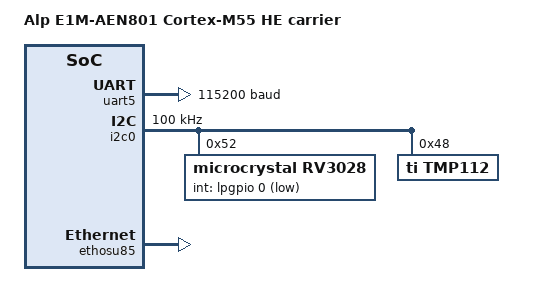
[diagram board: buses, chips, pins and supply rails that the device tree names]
/*
 * Copyright (c) 2026 Alp Lab AB
 * SPDX-License-Identifier: Apache-2.0
 * Auto-generated by `scripts/alp_project.py --emit zephyr-board` from
 * metadata/e1m_modules/E1M-AEN801.yaml + metadata/socs/alif/ensemble/e8.json + metadata/e1m_modules/aen/on-module-links.yaml.
 * DO NOT EDIT BY HAND -- regenerate.
 *
 * E1M-AEN801 (Alif Ensemble E8, AE822FA0E5597LS0) Cortex-M55-HE carrier,
 * for the Alp E1M-EVK.
 *
 * Reuses the upstream Alif E8 SoC + RTSS-HE cluster devicetree and:
 *   - retargets the console from the DevKit's UART2 to the E1M carrier console
 *     (Alif UART5, P3_4/P3_5 -- the E1M edge "UART0");
 *   - runs boot + storage from on-die MRAM only.  The SoM's OSPI0 NOR
 *     (MX25UM25645) + HyperRAM (W958D8NB) are BOM-optional and NOT populated
 *     on the current batch, so there is no external XIP / flash device;
 *   - lays down a production MCUboot partition map in MRAM.
 *
 * NOTE (AMP, #1069): HE's slot0 lives in its OWN disjoint MRAM window,
 * physically separate from HP's -- both cores' images can be
 * resident in MRAM at once (see the partition map below and
 * metadata/e1m_modules/E1M-AEN801.yaml `memory_map:`).  OTA is DEFERRED
 * (CONFIG_SINGLE_APPLICATION_SLOT=y, no secondary/scratch slot): the
 * per-core code slots (HE 2688 KiB + HP 2688 KiB) share the
 * 5632 KiB App MRAM with boot, storage and the NPU MRAM-model
 * budget -- see zephyr/sysbuild/aen/README.md for the sizing rationale.
 *
 * Inter-core IPC (the APSS<->RTSS-HE MHUv2 doorbell pair) + the remaining
 * on-module peripheral buses (GPIO / SPI / Ethernet) are added alongside the
 * alp-sdk Alif peripheral drivers; this base wires boot, console and the
 * on-module BRD_I2C housekeeping bus (RTC + temperature sensor, below).
 */

/dts-v1/;

#include <alif/ensemble/ae822fa0e5597ls0.dtsi>
#include <alif/ensemble/common/ensemble_rtss_he.dtsi>
#include <alif/ensemble_e8_peripherals.dtsi>
#include <zephyr/dt-bindings/gpio/gpio.h>
#include <zephyr/dt-bindings/i2c/i2c.h>
#include "alp_e1m_aen801_m55_he-pinctrl.dtsi"

/ {
	model = "Alp E1M-AEN801 Cortex-M55 HE carrier";
	compatible = "alp,e1m-aen801-m55-he";

	chosen {
		zephyr,flash = &mram_storage;
		/*
		 * MCUboot's flash_map_extended.c derives FLASH_DEVICE_BASE /
		 * FLASH_DEVICE_ID from zephyr,flash-controller (the controller
		 * node, NOT the soc-nv-flash child) -- mirrors the fork's
		 * e1.dtsi chosen.  Without it MCUboot's flash_map fails to link.
		 */
		zephyr,flash-controller = &mram;
		zephyr,sram = &dtcm;
		zephyr,console = &uart5;
		zephyr,shell-uart = &uart5;
		zephyr,code-partition = &slot0_partition;
	};
};

/*
 * ITCM/DTCM global_base -- central CPU-local -> system-bus address translation.
 *
 * hal_alif's soc_memory_map.h local_to_global() translates a CPU-local TCM
 * pointer into the address other bus masters (the Ethos-U NPU AXI master, the
 * SD/DMA controllers) must be programmed with, by reading
 * DT_PROP(DT_NODELABEL(itcm|dtcm), global_base).  Upstream Zephyr's
 * arm,itcm/arm,dtcm bindings (ensemble_rtss_he.dtsi, included above) declare no
 * such property, so re-`compatible` the nodes onto the alp-sdk
 * alif,itcm/alif,dtcm bindings (zephyr/dts/bindings/memory-controllers/), which
 * require global_base.  Done here in the per-core board (not a per-example
 * overlay) so every HE app on this board inherits the same translation.
 *
 * Values transcribed from the Apache-2.0 zephyr_alif fork
 * dts/arm/alif/ensemble/common/ensemble_rtss_he.dtsi:
 *   itcm global_base = 0x58000000  (also bench-known)
 *   dtcm global_base = 0x58800000
 * These are the RTSS-HE global TCM aliases; the RTSS-HP core uses a different
 * window (0x50000000 / 0x50800000), set in the _hp board dts.
 */
&itcm {
	/* fork ensemble_rtss_he.dtsi: itcm compatible = "alif,itcm" */
	compatible = "alif,itcm";
	/* fork ensemble_rtss_he.dtsi: itcm global_base = <0x58000000> */
	global_base = <0x58000000>;
};

&dtcm {
	/* fork ensemble_rtss_he.dtsi: dtcm compatible = "alif,dtcm" */
	compatible = "alif,dtcm";
	/* fork ensemble_rtss_he.dtsi: dtcm global_base = <0x58800000> */
	global_base = <0x58800000>;
};

/*
 * On-die MRAM as a real flash controller (ADR 0017 Tier-2).
 *
 * Upstream Zephyr's E8 SoC dtsi exposes the MRAM only as a memory region
 * (`mram: flash@80000000`, compatible "zephyr,memory-region","soc-nv-flash"):
 * XIP-readable but with NO flash driver, so FLASH_HAS_DRIVER_ENABLED stays
 * unset and MCUboot's flash_map has nothing to read/write slot0 with.
 *
 * We retarget the upstream `&mram` node into the fork's flash-controller
 * hierarchy WITHOUT editing upstream zephyr/: override `&mram`'s compatible to
 * the controller compatible "alif,mram-flash-controller" (which the in-tree
 * flash_mram_alif driver binds, setting FLASH_HAS_DRIVER_ENABLED), and add a
 * `mram_storage` soc-nv-flash child carrying the program/erase geometry the
 * driver reads (DT_NODELABEL(mram_storage): erase-block-size / write-block-size
 * / reg).  This mirrors the fork e1.dtsi node structure exactly (controller
 * `mram_flash@80000000` + `mram_storage@80000000` soc-nv-flash child); the only
 * difference is we reuse the upstream `mram` nodelabel as the controller rather
 * than declaring a fresh `mram_flash` node, since upstream owns the node.
 *
 * MRAM partition map (this HE core's 2944 KiB view of the
 * 5632 KiB App MRAM) for the sysbuild/aen MCUboot profile (MCUboot + a
 * signed application image, CONFIG_SINGLE_APPLICATION_SLOT=y -- no OTA/swap
 * slot, deferred per #1069).  Offsets are relative to the soc-nv-flash child
 * base (MRAM 0x80000000).  HP's disjoint slot0 window is NOT a
 * partition in this table (it's outside this core's own view); see
 * metadata/e1m_modules/E1M-AEN801.yaml `memory_map:` for the full physical map:
 *
 *   mcuboot  0x000000  64 KiB
 *   image-0  0x010000  2688 KiB   (primary slot, code-partition)
 *   reserved 0x550000  64 KiB   (ex-scratch; unused, OTA deferred)
 *   storage  0x560000  96 KiB    (settings / NVS)
 *   atoc     0x578000  32 KiB    (SE-owned: SETOOLS top-anchors the ATOC here -- do NOT write, #1289)
 *                      = 2944 KiB (of 5632 KiB App MRAM total)
 *
 * MRAM-only: the SoM OSPI NOR + HyperRAM are not populated on this batch, so
 * boot, this core's own slot0, reserved headroom, and storage all live in MRAM.
 */
&mram {
	compatible = "alif,mram-flash-controller";
	#address-cells = <1>;
	#size-cells = <1>;
	/*
	 * Drop the upstream memory-region properties: this node is no longer a
	 * "zephyr,memory-region" (it is a flash controller now), and the
	 * controller addresses its soc-nv-flash child by absolute `reg`, not via
	 * `ranges`.  flash-controller.yaml / base.yaml declare neither property,
	 * so they must be removed or DT binding-check fails.
	 */
	/delete-property/ zephyr,memory-region;
	/delete-property/ ranges;

	mram_storage: mram_storage@80000000 {
		compatible = "soc-nv-flash";
		reg = <0x80000000 DT_SIZE_K(5632)>;
		erase-block-size = <1024>;
		write-block-size = <16>;

		partitions {
			compatible = "fixed-partitions";
			#address-cells = <1>;
			#size-cells = <1>;

			boot_partition: partition@0 {
				label = "mcuboot";
				reg = <0x0 DT_SIZE_K(64)>;
			};

			slot0_partition: partition@10000 {
				label = "image-0";
				reg = <0x10000 DT_SIZE_K(2688)>;
			};

			reserved_partition: partition@550000 {
				label = "reserved";
				reg = <0x550000 DT_SIZE_K(64)>;
			};

			storage_partition: partition@560000 {
				label = "storage";
				reg = <0x560000 DT_SIZE_K(96)>;
			};

			atoc_partition: partition@578000 {
				label = "atoc";
				reg = <0x578000 DT_SIZE_K(32)>;
			};
		};
	};
};

/* Carrier console: Alif UART5 on P3_4 (RX) / P3_5 (TX), 115200 8N1. */
&uart5 {
	status = "okay";
	pinctrl-0 = <&pinctrl_uart5>;
	pinctrl-names = "default";
	current-speed = <115200>;
};

/*
 * BRD_I2C -- the on-module housekeeping bus: SoC I2C0 in its function-C
 * muxing (P7_0 SDA / P7_1 SCL), NOT the slave-only LPI2C0 it was
 * believed to be before #1848.  Driven by UPSTREAM
 * Zephyr i2c_dw ("snps,designware-i2c"), ADR 0017 Tier-1 -- no vendored code.
 *
 * ISOLATED: R93/R94 (the 0-ohm bridge to the I2C2/EEPROM segment) are DNP, so
 * the 24C128 manifest EEPROM is NOT on this bus -- it stays on i2c2.  The
 * OPTIGA Trust M (IC1, @0x30) is DNP=1 on this batch and so has NO node here;
 * its silence is a negative control, not a fault.
 *
 * Both device drivers are upstream and Kconfig `default y` on their own
 * DT_HAS_*_ENABLED, so an app needs only CONFIG_RTC / CONFIG_SENSOR in its
 * prj.conf -- the board layer deliberately forces neither.
 */
&i2c0 {
	status = "okay";
	pinctrl-0 = <&pinctrl_i2c0>;
	pinctrl-names = "default";
	clock-frequency = <I2C_BITRATE_STANDARD>;

	/*
	 * E1M-AEN-2626-R2 components CSV: U21 = RV-3028-C7, DNP=0 fitted. Bench
	 * 2026-09-05: ACKs at 0x52, ID register 0x28 reads 0x44, and the seconds
	 * register advanced 0x01 -> 0x02, so the oscillator is RUNNING. CAVEAT for
	 * docs and examples: with no VBACKUP cell the RTC does NOT retain time or a
	 * pending alarm across a power cycle on this batch.
	 */
	rv3028: rtc@52 {
		compatible = "microcrystal,rv3028";
		reg = <0x52>;
		backup-switch-mode = "disabled";
		int-gpios = <&lpgpio 0 GPIO_ACTIVE_LOW>;
	};

	/*
	 * E1M-AEN-2626-R2 components CSV: U20 = TMP112DIDPWR, DNP=0 fitted, ADD0 tied
	 * to 0V. The TMP112 strap table is ADD0->GND = 0x48, ->V+ = 0x49, ->SDA =
	 * 0x4A, ->SCL = 0x4B, so 0x48 is the DESIGN address. ANOMALY, do not "fix"
	 * this to match it: one bench unit (2026-09-05) answered at 0x40 -- not a
	 * legal TMP112 address at all -- while confirming a three-of-three TMP112
	 * register fingerprint there (CONFIG=0x60a0, T_LOW=0x4b00, T_HIGH=0x5000, the
	 * datasheet power-on defaults; read 28.062 degC). That points at ADD0 not
	 * actually sitting at GND on that module (suspected open joint on U20 pin 3):
	 * a defect on ONE unit, not the design. The shipped devicetree carries 0x48;
	 * examples tolerate and report the observed 0x40.
	 */
	tmp112: tmp112@48 {
		compatible = "ti,tmp112";
		reg = <0x48>;
	};
};

/*
 * lpgpio -- needed so the RV-3028 alarm on P15_0 (RTC_ALARM, bit 0 =>
 * IRQ 171) is usable as an interrupt source.  Active LOW,
 * open-drain, pulled up on-module by R98 (100k to +1V8, FITTED).  The pad
 * itself is muxed in the pinctrl dtsi's BRD_I2C group (that binding has no
 * pinctrl-0 of its own).
 *
 * The AE822 DFP warns for port 15: "Note that LPGPIO_CTRL_n register has a
 * different layout!". That is the most likely bench failure on this alarm path
 * and must NOT be mistaken for an RTC fault -- if the alarm never fires,
 * suspect the port-15 control-register layout before suspecting U21.
 */
&lpgpio {
	status = "okay";
};

/*
 * Portable aliases.  The bus alias is what alp_i2c_open(.bus_id = N)
 * resolves (src/backends/i2c/zephyr_drv.c -> DT_ALIAS(alp_i2cN)), matching
 * the on-module EEPROM's own convention on i2c2; the device aliases let an
 * example say DT_ALIAS(rtc) / DT_ALIAS(ambient_temp0) instead of hardcoding
 * this board's node labels.
 */
/ {
	aliases {
		alp-i2c2 = &i2c0;
		rtc = &rv3028;
		ambient-temp0 = &tmp112;
	};
};

/* Arm Ethos-U NPU: enable the ethosu85 node declared in the SoC peripherals dtsi (see ALP_SDK_INFERENCE_BACKEND_ETHOS_U_AEN). */
&ethosu85 {
	status = "okay";
};
